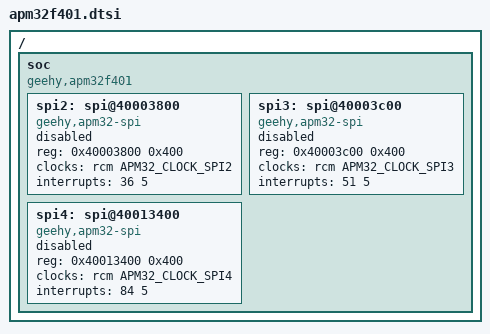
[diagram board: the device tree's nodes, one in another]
/*
 * Copyright (c) 2023, Quincy.W <wangqyfm@foxmail.com>
 * SPDX-License-Identifier: Apache-2.0
 */

#include <geehy/f4/apm32f4.dtsi>

/ {
	soc {
		compatible = "geehy,apm32f401", "geehy,apm32f4", "simple-bus";

		spi2: spi@40003800 {
			compatible = "geehy,apm32-spi";
			#address-cells = <1>;
			#size-cells = <0>;
			reg = <0x40003800 0x400>;
			clocks = <&rcm APM32_CLOCK_SPI2>;
			interrupts = <36 5>;
			status = "disabled";
		};

		spi3: spi@40003c00 {
			compatible = "geehy,apm32-spi";
			#address-cells = <1>;
			#size-cells = <0>;
			reg = <0x40003c00 0x400>;
			clocks = <&rcm APM32_CLOCK_SPI3>;
			interrupts = <51 5>;
			status = "disabled";
		};

		spi4: spi@40013400 {
			compatible = "geehy,apm32-spi";
			#address-cells = <1>;
			#size-cells = <0>;
			reg = <0x40013400 0x400>;
			clocks = <&rcm APM32_CLOCK_SPI4>;
			interrupts = <84 5>;
			status = "disabled";
		};
	};
};
